# MKE15D7 register map
File version: 1.6
Registers are 32-bit, read-write, reset 0x0 unless marked. A register's access mark holds for its fields unless they carry their own. Offsets are from the block's base; [hi:lo] are bit positions; {n}, {i} and the like mark numbered series.

## ADC0 — Analog-to-digital converter
Base 0x4003B000; register names take the prefix ADC0_
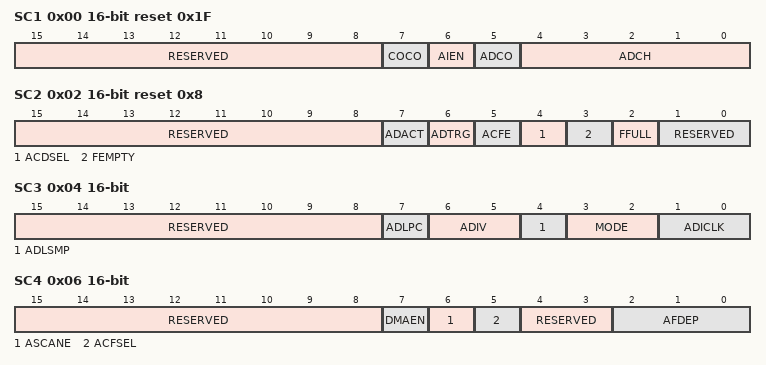
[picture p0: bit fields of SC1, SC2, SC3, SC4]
0x00 SC1 16-bit reset 0x1F — Status and Control Register 1
  [15:8] RESERVED ro
  [7] COCO ro — Conversion Complete Flag
    0=Conversion not completed; 1=Conversion completed
  [6] AIEN — Interrupt Enable
    0=Conversion complete interrupt disabled; 1=Conversion complete interrupt enabled
  [5] ADCO — Continuous Conversion Enable
    0=One conversion following a write to the ADCSC1 when software triggered operation is selected, or one conversion following assertion of ADHWT when hardware triggered operation is selected. When the FIFO function is enabled (AFDEP > 0), a set of conversions are triggerd.; 1=Continuous conversions initiated following a write to ADCSC1 when software triggered operation is selected. Continuous conversions are initiated by an ADHWT event when hardware triggered operation is selected. When the FIFO function is enabled (AFDEP > 0), a set of conversions are loop triggered.
  [4:0] ADCH — Input Channel Select
    {v}=AD{v} (v=0..11); 31=Module disabled Reset FIFO in FIFO mode
0x02 SC2 16-bit reset 0x8 — Status and Control Register 2
  [15:8] RESERVED ro
  [7] ADACT ro — Conversion Active
    0=Conversion not in progress; 1=Conversion in progress
  [6] ADTRG — Conversion Trigger Select
    0=Software trigger selected; 1=Hardware trigger selected
  [5] ACFE — Compare Function Enable
    0=Compare function disabled; 1=Compare function enabled
  [4] ACDSEL — Compare Data Selection
    0=Compare value is from the conversion result and ADC_CVA; 1=Compare value is from the conversion result and ADC_CVB
  [3] FEMPTY ro — Result FIFO empty
    0=Indicates that ADC result fifo have at least one valid new data; 1=Indicates that ADC result fifo have no valid new data
  [2] FFULL ro — Result FIFO full
    0=Indicates that ADC result fifo is not full and next conversion data still can be stored into fifo; 1=Indicates that ADC result fifo is full and next conversion will override old data if no read action
  [1:0] RESERVED ro
0x04 SC3 16-bit — Status and Control Register 3
  [15:8] RESERVED ro
  [7] ADLPC — Low-Power Configuration
    0=High speed configuration; 1=Low power configuration:The power is reduced at the expense of maximum clock speed
  [6:5] ADIV — Clock Divide Select
    0=Divide ration = 1, and clock rate = Input clock; 1=Divide ration = 2, and clock rate = Input clock * 2; 2=Divide ration = 3, and clock rate = Input clock * 4; 3=Divide ration = 4, and clock rate = Input clock * 8
  [4] ADLSMP — Long Sample Time Configuration
    0=Short sample time; 1=Long sample time
  [3:2] MODE — Conversion Mode Selection
    0=8-bit conversion (N=8); 1=10-bit conversion (N=10); 2=12-bit conversion (N=12)
  [1:0] ADICLK — Input Clock Select
    0=Bus clock; 1=Bus clock divided by 2; 2=Alternate clock (ALTCLK); 3=Asynchronous clock (ADACK)
0x06 SC4 16-bit — Status and Control Register 4
  [15:8] RESERVED ro
  [7] DMAEN — DMA Enable
    0=DMA read request is disabled; 1=DMA read request is enabled, the conversion complete flag will assert the DMA request signal
  [6] ASCANE
    0=FIFO scan mode disabled; 1=FIFO scan mode enabled
  [5] ACFSEL
    0=OR all of compare trigger; 1=AND all of compare trigger
  [4:3] RESERVED ro
  [2:0] AFDEP
    0=FIFO is disabled; {v}={v+1}-level FIFO is enabled (v=1..7)
0x08 R 16-bit ro — Conversion Result Register
  [15:0] ADR — Conversion Result
0x0A CVA 16-bit — Compare Value Register A
  [15:0] VA — Lower limit compare value
0x0C CVB 16-bit — Compare Value Register B
  [15:0] VB — Upper limit compare value
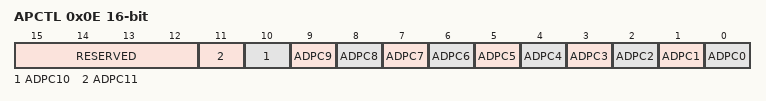
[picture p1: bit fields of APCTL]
0x0E APCTL 16-bit — Pin Control Register
  [15:12] RESERVED ro
  [n] ADPC{n} (n=0..11) — ADC Pin Control {n}
    0=AD{n} pin I/O control enabled; 1=AD{n} pin I/O control disabled

## ADC1 — Analog-to-digital converter
Base 0x4003C000; register names take the prefix ADC1_
Registers as ADC0.

## ADC2 — Analog-to-digital converter
Base 0x4003D000; register names take the prefix ADC2_
Registers as ADC0.

## ADC3 — Analog-to-digital converter
Base 0x4003E000; register names take the prefix ADC3_
Registers as ADC0.
